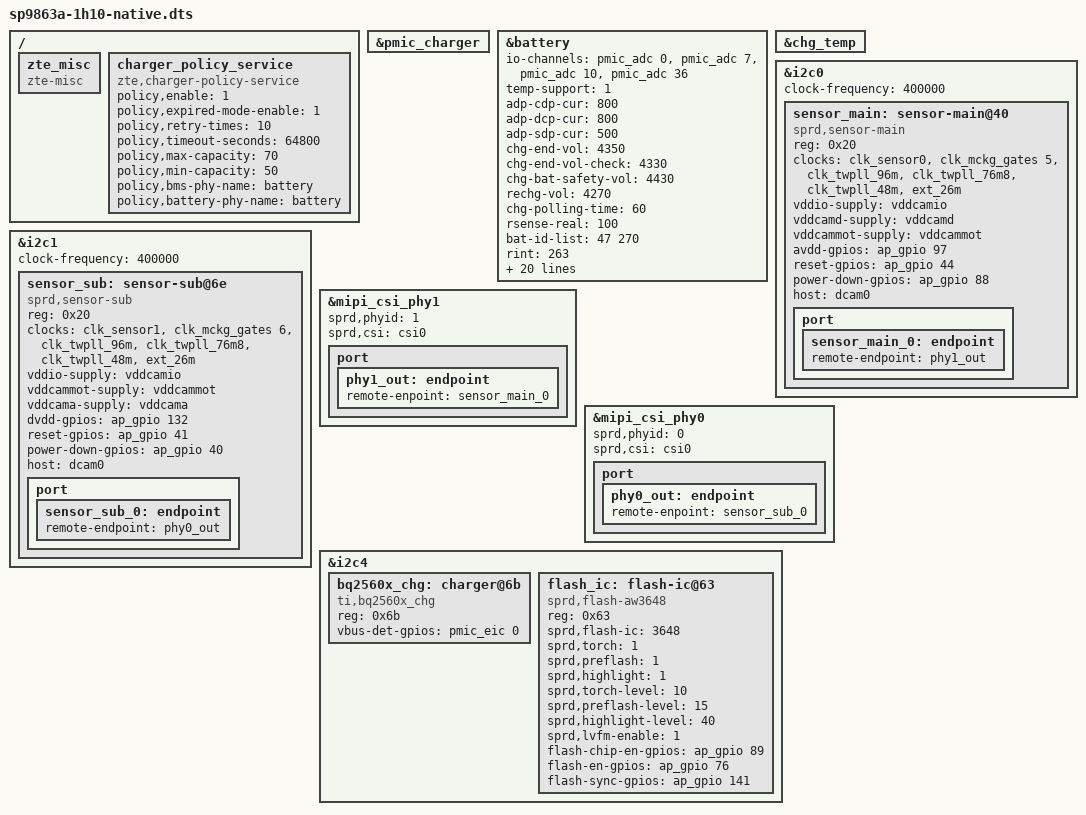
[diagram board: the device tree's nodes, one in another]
/*****************************************
Do not modify dts file, please modify according dtsi file
******************************************/

#include "../sp9863a-1h10-native.dts"
#include "sprd_base_diff.dtsi"

/ {
	zte_misc: zte_misc {
		status = "okay";
		compatible = "zte-misc";
	};

	charger_policy_service {
		compatible = "zte,charger-policy-service";
		status="okay";
		policy,enable = <1>;
		policy,expired-mode-enable = <1>;
		policy,retry-times = <10>;
		policy,timeout-seconds = <64800>;/* 18 hours */
		policy,max-capacity = <70>;
		policy,min-capacity = <50>;
		policy,bms-phy-name = "battery";
		policy,battery-phy-name = "battery";
	};
};

&pmic_charger {
	status = "okay";
};

&battery {
	io-channels = <&pmic_adc 0>,<&pmic_adc 7>,<&pmic_adc 10>,
			<&pmic_adc 36>;
	io-channel-names = "adc_batt_id","adc_temp","adc_vbat",
			"adc_vchg";
	temp-support = <1>;
	adp-cdp-cur = <800>;
	adp-dcp-cur = <800>;
	adp-sdp-cur = <500>;
	chg-end-vol = <4350>;
	chg-end-vol-check = <4330>;
	chg-bat-safety-vol = <4430>;
	rechg-vol = <4270>;
	chg-polling-time = <60>;
	rsense-real = <100>;
	bat-id-list = <47 270>; /* battery id kohm */
	rint = <263>;
	cnom = <2702>;
	ocv-tab-vol = <4322 4229 4168 4133 4068 4004 3968
			3930 3894 3858 3814 3792 3779 3776
			3774 3767 3746 3699 3602 3529 3400>;
	rint-1 = <221>;
	cnom-1 = <2646>;
	ocv-tab-vol-1 = <4323 4242 4181 4126 4075 4021 3978
			3939 3903 3864 3821 3799 3784 3775
			3773 3764 3747 3725 3676 3567 3400>;
	ocv-tab-cap = <100  95   90   85   80   75   70
			65   60   55   50   45   40   35
			30   25   20   15   10   5    0>;
	/*30mohm,if temp-table-mode = <1>, use it*/
	temp-comp-res = <30>;
	temp-tab-val = <1124 1104 1079 1047 1010 967
			917 861 801 738 672 607
			543 482 425 372 325 282 243>;
	/* temperature + 1000,750 = 1000 + (-250)*/
	temp-tab-temp = <750 800 850 900 950 1000
			1050 1100 1150 1200 1250 1300
			1350 1400 1450 1500 1550 1600 1650>;
	jeita-temp-tab = <1000 1050 1150 1450 1550>;
	jeita-temp-recovery-tab = <1030 1080 1180 1420 1520>;
	jeita-cur-tab = <0 700 700 0x7FFF 700 0>;
	jeita-cccv-tab = <4350 4350 4350 4350 4100 4100>;
	batt_full_design_capacity = <2000>;
};

&chg_temp {
	status = "okay";
};

/*****************************************
cam setting
******************************************/
&i2c0 {
	/delete-node/ sensor-main@20;
};

&i2c1 {
	/delete-node/ sensor-sub@20;
};

&i2c0 {
	status = "okay";
	clock-frequency = <400000>;

	sensor_main: sensor-main@40 {
		compatible = "sprd,sensor-main";
		reg = <0x20>;
		clock-names = "clk_src","sensor_eb",
			"clk_96m","clk_76m8",
			"clk_48m","clk_26m";
		clocks = <&clk_sensor0>, <&clk_mckg_gates 5>,
			<&clk_twpll_96m>,<&clk_twpll_76m8>,
			<&clk_twpll_48m>,<&ext_26m>;
		vddio-supply = <&vddcamio>;
		vddcamd-supply = <&vddcamd>;
		vddcammot-supply = <&vddcammot>;
		avdd-gpios=<&ap_gpio 97 0>;
		reset-gpios = <&ap_gpio 44 0>;
		power-down-gpios = <&ap_gpio 88 0>;
		host = "dcam0";
		port {
			sensor_main_0: endpoint {
				remote-endpoint = <&phy1_out>;
			};
		};
	};
};

&i2c1 {
	status = "okay";
	clock-frequency = <400000>;

	sensor_sub: sensor-sub@6e {
		compatible = "sprd,sensor-sub";
		reg = <0x20>;
		clock-names = "clk_src","sensor_eb",
			"clk_96m","clk_76m8",
			"clk_48m","clk_26m";
		clocks = <&clk_sensor1>, <&clk_mckg_gates 6>,
			<&clk_twpll_96m>,<&clk_twpll_76m8>,
			<&clk_twpll_48m>,<&ext_26m>;
		vddio-supply = <&vddcamio>;
		vddcammot-supply = <&vddcammot>;
		vddcama-supply = <&vddcama>;
		dvdd-gpios=<&ap_gpio 132 0>;
		reset-gpios = <&ap_gpio 41 0>;
		power-down-gpios = <&ap_gpio 40 0>;
		host = "dcam0";
		port {
			sensor_sub_0: endpoint {
				remote-endpoint = <&phy0_out>;
			};
		};
	};
};

&mipi_csi_phy1 {
	status = "okay";
	sprd,phyid = <1>;
	sprd,csi = <&csi0>;
	status = "okay";
	port {
		phy1_out: endpoint {
			remote-enpoint = <&sensor_main_0>;
		};
	};
};


&mipi_csi_phy0 {
	status = "okay";
	sprd,phyid = <0>;
	sprd,csi = <&csi0>;
	status = "okay";
	port {
		phy0_out: endpoint {
			remote-enpoint = <&sensor_sub_0>;
		};
	};
};

&i2c4 {
	/delete-node/ flash-ic@63;
};

&i2c4 {
	bq2560x_chg: charger@6b {
		compatible = "ti,bq2560x_chg";
		reg = <0x6b>;
		vbus-det-gpios = <&pmic_eic 0 0>;
	};

	flash_ic: flash-ic@63 {
		compatible = "sprd,flash-aw3648";
		reg = <0x63>;
		sprd,flash-ic = <3648>;
		sprd,torch = <1>;
		sprd,preflash = <1>;
		sprd,highlight = <1>;
		sprd,torch-level = <10>;
		sprd,preflash-level = <15>;
		sprd,highlight-level = <40>;
		sprd,lvfm-enable = <1>;
		flash-chip-en-gpios = <&ap_gpio 89 0>;
		flash-en-gpios = <&ap_gpio 76 0>;
		flash-sync-gpios = <&ap_gpio 141 0>;
	};
};


